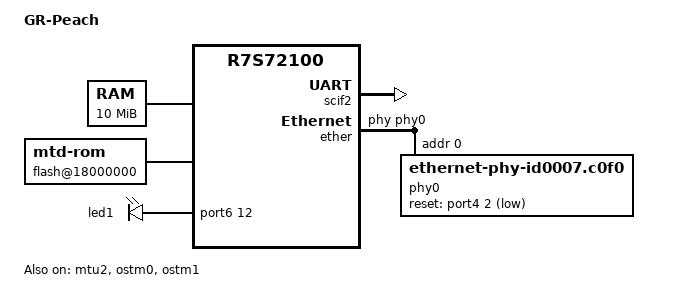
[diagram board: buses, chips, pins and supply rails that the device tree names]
/dts-v1/;
#include "r7s72100.dtsi"
#include <dt-bindings/gpio/gpio.h>
#include <dt-bindings/pinctrl/r7s72100-pinctrl.h>
/ {
	model = "GR-Peach";
	compatible = "renesas,gr-peach", "renesas,r7s72100";
	aliases {
		serial0 = &scif2;
	};
	chosen {
		bootargs = "ignore_loglevel rw root=/dev/mtdblock0";
		stdout-path = "serial0:115200n8";
	};
	memory@20000000 {
		device_type = "memory";
		reg = <0x20000000 0x00a00000>;
	};
	lbsc {
		#address-cells = <1>;
		#size-cells = <1>;
	};
	flash@18000000 {
		compatible = "mtd-rom";
		probe-type = "map_rom";
		reg = <0x18000000 0x00800000>;
		bank-width = <4>;
		device-width = <1>;
		clocks = <&mstp9_clks R7S72100_CLK_SPIBSC0>;
		power-domains = <&cpg_clocks>;
		#address-cells = <1>;
		#size-cells = <1>;
		rootfs@600000 {
			label = "rootfs";
			reg = <0x00600000 0x00200000>;
		};
	};
	leds {
		status = "okay";
		compatible = "gpio-leds";
		led1 {
			gpios = <&port6 12 GPIO_ACTIVE_HIGH>;
		};
	};
};
&pinctrl {
	scif2_pins: serial2 {
		pinmux = <RZA1_PINMUX(6, 2, 7)>, <RZA1_PINMUX(6, 3, 7)>;
	};
	ether_pins: ether {
		pinmux = <RZA1_PINMUX(1, 14, 4)>,  
			 <RZA1_PINMUX(3, 0, 2)>,   
			 <RZA1_PINMUX(3, 3, 2)>,   
			 <RZA1_PINMUX(3, 4, 2)>,   
			 <RZA1_PINMUX(3, 5, 2)>,   
			 <RZA1_PINMUX(3, 6, 2)>,   
			 <RZA1_PINMUX(5, 9, 2)>,   
			 <RZA1_PINMUX(10, 1, 4)>,  
			 <RZA1_PINMUX(10, 2, 4)>,  
			 <RZA1_PINMUX(10, 3, 4)>,  
			 <RZA1_PINMUX(10, 4, 4)>,  
			 <RZA1_PINMUX(10, 5, 4)>,  
			 <RZA1_PINMUX(10, 6, 4)>,  
			 <RZA1_PINMUX(10, 7, 4)>,  
			 <RZA1_PINMUX(10, 8, 4)>,  
			 <RZA1_PINMUX(10, 9, 4)>,  
			 <RZA1_PINMUX(10, 10, 4)>, 
			 <RZA1_PINMUX(10, 11, 4)>; 
	};
};
&extal_clk {
	clock-frequency = <13333000>;
};
&usb_x1_clk {
	clock-frequency = <48000000>;
};
&mtu2 {
	status = "okay";
};
&ostm0 {
	status = "okay";
};
&ostm1 {
	status = "okay";
};
&scif2 {
	pinctrl-names = "default";
	pinctrl-0 = <&scif2_pins>;
	status = "okay";
};
&ether {
	pinctrl-names = "default";
	pinctrl-0 = <&ether_pins>;
	status = "okay";
	renesas,no-ether-link;
	phy-handle = <&phy0>;
	phy0: ethernet-phy@0 {
		compatible = "ethernet-phy-id0007.c0f0",
			     "ethernet-phy-ieee802.3-c22";
		reg = <0>;
		reset-gpios = <&port4 2 GPIO_ACTIVE_LOW>;
		reset-delay-us = <5>;
	};
};
